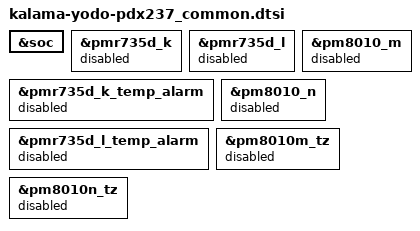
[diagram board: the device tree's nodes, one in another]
/* arch/arm64/boot/dts/qcom/kalama-yodo-pdx237_common.dtsi */

#include "kalama-yodo-common.dtsi"

&soc {
};

/* GPIO_159 : NC */
 /* Follow QC */

/* GPIO_160 : NC */
 /* Follow QC */

/* GPIO_161 : NC */
 /* Follow QC */

/* GPIO_186 : CS35L45_GPIO3 */
 /* Don't set here */

#include "somc-charger-yodo-common.dtsi"
#include "somc-charger-yodo-pdx237.dtsi"
#include "lxs_touchscreen_pdx234.dtsi"
#include "lxs_touchscreen_pdx237.dtsi"

/*
 * pdx237 không gắn pmr735d / pm8010 SPMI — chỉ dùng rpmh regulators pm8010m_l*.
 * Tắt node QRD để tránh probe fail trong logcat.
 */
&pmr735d_k {
	status = "disabled";
};

&pmr735d_l {
	status = "disabled";
};

&pmr735d_k_temp_alarm {
	status = "disabled";
};

&pmr735d_l_temp_alarm {
	status = "disabled";
};

&pm8010_m {
	status = "disabled";
};

&pm8010_n {
	status = "disabled";
};

&pm8010m_tz {
	status = "disabled";
};

&pm8010n_tz {
	status = "disabled";
};
